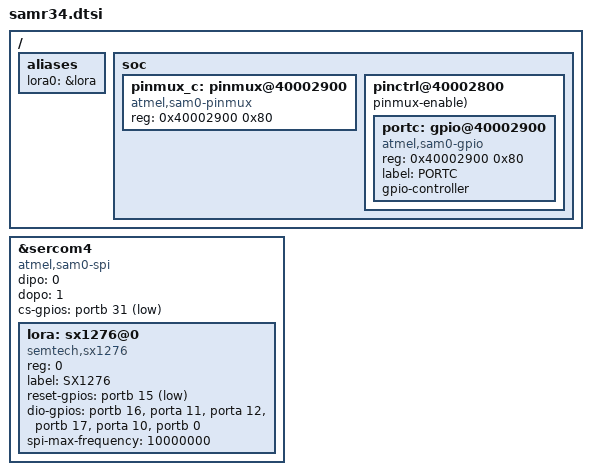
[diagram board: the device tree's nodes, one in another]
/*
 * Copyright (c) 2021 Argentum Systems Ltd.
 *
 * SPDX-License-Identifier: Apache-2.0
 */

#include <atmel/saml21.dtsi>
#include <dt-bindings/lora/sx126x.h>

/ {
	aliases {
		lora0 = &lora;
	};

	soc {
		pinmux_c: pinmux@40002900 {
			compatible = "atmel,sam0-pinmux";
			reg = <0x40002900 0x80>;
		};

		pinctrl@40002800 {
			ranges = <0x40002800 0x40002800 0x180>;

			portc: gpio@40002900 {
				compatible = "atmel,sam0-gpio";
				reg = <0x40002900 0x80>;
				label = "PORTC";
				gpio-controller;
				#gpio-cells = <2>;
				#atmel,pin-cells = <2>;
			};

			/* Internal SPI link to SX127x radio */
			DT_ATMEL_PORT(sercom4, pad2, b, 30, f, pinmux-enable);
			DT_ATMEL_PORT(sercom4, pad1, b, 31, f, pinmux-enable);
			DT_ATMEL_PORT(sercom4, pad3, c, 18, f, pinmux-enable);
			DT_ATMEL_PORT(sercom4, pad0, c, 19, f, pinmux-enable);
		};
	};
};

/delete-node/ &dac;

&sercom4 {
	/* SERCOM4 will typically used to interface with the internal LoRa radio */
	compatible = "atmel,sam0-spi";
	dipo = <0>;
	dopo = <1>;
	cs-gpios = <&portb 31 GPIO_ACTIVE_LOW>;
	#address-cells = <1>;
	#size-cells = <0>;

	lora: sx1276@0 {
		compatible = "semtech,sx1276";
		reg = <0>;
		label = "SX1276";
		reset-gpios = <&portb 15 GPIO_ACTIVE_LOW>;           /* nRST */
		dio-gpios =
			<&portb 16 (GPIO_PULL_DOWN | GPIO_ACTIVE_HIGH)>, /* DIO0 */
			<&porta 11 (GPIO_PULL_DOWN | GPIO_ACTIVE_HIGH)>, /* DIO1 */
			<&porta 12 (GPIO_PULL_DOWN | GPIO_ACTIVE_HIGH)>, /* DIO2 */
			<&portb 17 (GPIO_PULL_DOWN | GPIO_ACTIVE_HIGH)>, /* DIO3 */
			<&porta 10 (GPIO_PULL_DOWN | GPIO_ACTIVE_HIGH)>, /* DIO4 */
			<&portb  0 (GPIO_PULL_DOWN | GPIO_ACTIVE_HIGH)>; /* DIO5 */
		spi-max-frequency = <10000000>;
	};
};
